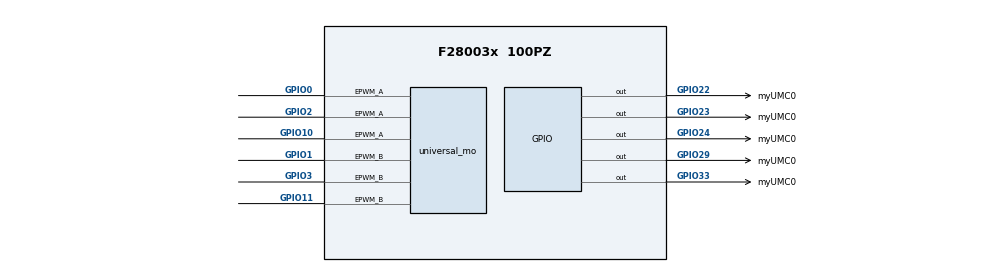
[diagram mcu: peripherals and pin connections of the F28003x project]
/**
 * @cliArgs --device "F28003x" --package "100PZ" --part "F28003x_100PZ" --product "C2000MCSDK@1.00.00.00"
 * @versions {"tool":"1.0.0+dev"}
 */

/**
 * Import the modules used in this configuration.
 */
const asysctl                  = scripting.addModule("/driverlib/asysctl.js");
const universal_motor_control  = scripting.addModule("/solutions/universal_motor_control.js", {}, false);
const universal_motor_control1 = universal_motor_control.addInstance();

/**
 * Write custom configuration values to the imported modules.
 */
asysctl.enableTemperatureSensor = true;
asysctl.analogReference         = "INTERNAL";
asysctl.analogReferenceVoltage  = "1P65";

universal_motor_control1.$name                                 = "myUMC0";
universal_motor_control1.motor1_epwm_U.epwm.$assign            = "EPWM1";
universal_motor_control1.motor1_epwm_U.epwm.epwm_aPin.$assign  = "GPIO0";
universal_motor_control1.motor1_epwm_U.epwm.epwm_bPin.$assign  = "GPIO1";
universal_motor_control1.motor1_epwm_V.epwm.$assign            = "EPWM2";
universal_motor_control1.motor1_epwm_V.epwm.epwm_aPin.$assign  = "GPIO2";
universal_motor_control1.motor1_epwm_V.epwm.epwm_bPin.$assign  = "GPIO3";
universal_motor_control1.motor1_epwm_W.epwm.$assign            = "EPWM6";
universal_motor_control1.motor1_epwm_W.epwm.epwm_aPin.$assign  = "GPIO10";
universal_motor_control1.motor1_epwm_W.epwm.epwm_bPin.$assign  = "GPIO11";
universal_motor_control1.motor1_gate_en_gpio.gpioPin.$assign   = "GPIO29";
universal_motor_control1.motor1_gate_mode_gpio.gpioPin.$assign = "GPIO33";
universal_motor_control1.motor1_gate_gain_gpio.gpioPin.$assign = "GPIO22";
universal_motor_control1.motor1_gate_cal_gpio.gpioPin.$assign  = "GPIO23";
universal_motor_control1.motor1_pm_nfault_gpio.gpioPin.$assign = "GPIO24";

const analog                                 = scripting.addModule("/driverlib/analog.js", {}, false);
const analog1                                = analog.addInstance({}, false);
analog1.$name                                = "myANALOGPinMux0";
universal_motor_control1.cmpss_CMPSS3.analog = analog1;
universal_motor_control1.cmpss_CMPSS1.analog = analog1;
universal_motor_control1.adc_ADCC.analog     = analog1;
universal_motor_control1.adc_ADCB.analog     = analog1;
universal_motor_control1.adc_ADCA.analog     = analog1;

/**
 * Pinmux solution for unlocked pins/peripherals. This ensures that minor changes to the automatic solver in a future
 * version of the tool will not impact the pinmux you originally saw.  These lines can be completely deleted in order to
 * re-solve from scratch.
 */
analog1.analog.$suggestSolution                           = "ANALOG";
analog1.analog["a0/b15/c15/daca_outPin"].$suggestSolution = "A0/B15/C15/DACA_OUT";
analog1.analog["a1/b7/dacb_outPin"].$suggestSolution      = "A1/B7/DACB_OUT";
analog1.analog["a10/b1/c10Pin"].$suggestSolution          = "A10/B1/C10";
analog1.analog["a11/b10/c0Pin"].$suggestSolution          = "A11/B10/C0";
analog1.analog["a12, c5Pin"].$suggestSolution             = "A12, C5";
analog1.analog["a14/b14/c4Pin"].$suggestSolution          = "A14/B14/C4";
analog1.analog["a2/b6/c9Pin"].$suggestSolution            = "A2/B6/C9";
analog1.analog["a3, c7/b9Pin"].$suggestSolution           = "A3, C7/B9";
analog1.analog["a4/b8Pin"].$suggestSolution               = "A4/B8";
analog1.analog.a5Pin.$suggestSolution                     = "A5";
analog1.analog.a6Pin.$suggestSolution                     = "A6";
analog1.analog.a8Pin.$suggestSolution                     = "A8";
analog1.analog.a9Pin.$suggestSolution                     = "A9";
analog1.analog["b0/c11Pin"].$suggestSolution              = "B0/C11";
analog1.analog.b11Pin.$suggestSolution                    = "B11";
analog1.analog["b11, gpio21Pin"].$suggestSolution         = "B11, GPIO21";
analog1.analog["b2/c6Pin"].$suggestSolution               = "B2/C6";
analog1.analog["b3/vdacPin"].$suggestSolution             = "B3/VDAC";
analog1.analog["b4/c8Pin"].$suggestSolution               = "B4/C8";
analog1.analog.b5Pin.$suggestSolution                     = "B5";
analog1.analog["b5, gpio20Pin"].$suggestSolution          = "B5, GPIO20";
analog1.analog.c1Pin.$suggestSolution                     = "C1";
analog1.analog.c14Pin.$suggestSolution                    = "C14";
analog1.analog["c2/b12Pin"].$suggestSolution              = "C2/B12";
analog1.analog["c3/a7Pin"].$suggestSolution               = "C3/A7";
